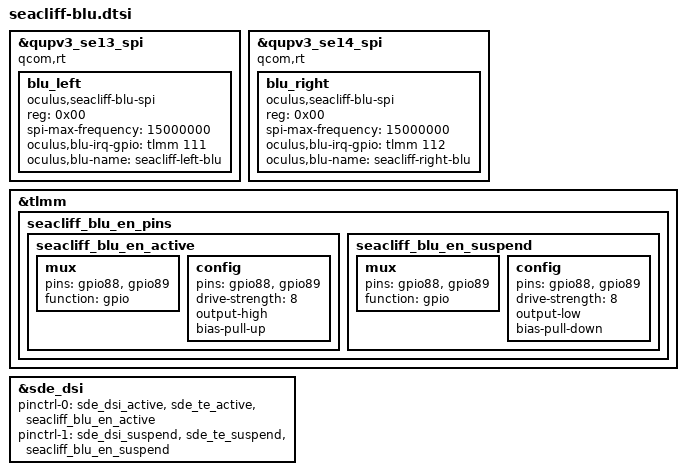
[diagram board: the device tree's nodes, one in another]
// SPDX-License-Identifier: GPL-2.0

&qupv3_se13_spi {
	status = "ok";
	qcom,rt;

	blu_left {
		compatible = "oculus,seacliff-blu-spi";
		reg = <0x00>;
		spi-max-frequency = <15000000>;
		oculus,blu-irq-gpio = <&tlmm 111 0>;
		oculus,blu-name = "seacliff-left-blu";
	};
};

&qupv3_se14_spi {
	status = "ok";
	qcom,rt;

	blu_right {
		compatible = "oculus,seacliff-blu-spi";
		reg = <0x00>;
		spi-max-frequency = <15000000>;
		oculus,blu-irq-gpio = <&tlmm 112 0>;
		oculus,blu-name = "seacliff-right-blu";
	};
};

&tlmm {
	seacliff_blu_en_pins {
		seacliff_blu_en_active: seacliff_blu_en_active {
			mux {
				pins = "gpio88", "gpio89";
				function = "gpio";
			};

			config {
				pins = "gpio88", "gpio89";
				drive-strength = <8>;
				output-high;
				bias-pull-up;
			};
		};
		seacliff_blu_en_suspend: seacliff_blu_en_suspend {
			mux {
				pins = "gpio88", "gpio89";
				function = "gpio";
			};

			config {
				pins = "gpio88", "gpio89";
				drive-strength = <8>;
				output-low;
				bias-pull-down;
			};
		};
	};
};

&sde_dsi {
	pinctrl-0 = <&sde_dsi_active &sde_te_active &seacliff_blu_en_active>;
	pinctrl-1 = <&sde_dsi_suspend &sde_te_suspend &seacliff_blu_en_suspend>;
};
